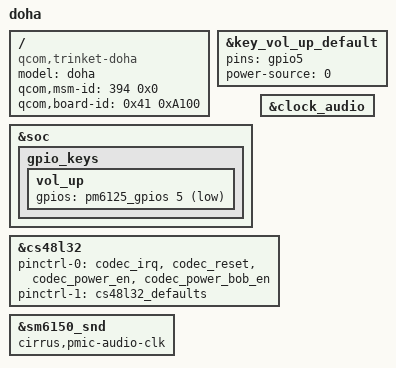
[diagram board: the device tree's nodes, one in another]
/* Copyright (c) 2018, The Linux Foundation. All rights reserved.
 *
 * This program is free software; you can redistribute it and/or modify
 * it under the terms of the GNU General Public License version 2 and
 * only version 2 as published by the Free Software Foundation.
 *
 * This program is distributed in the hope that it will be useful,
 * but WITHOUT ANY WARRANTY; without even the implied warranty of
 * MERCHANTABILITY or FITNESS FOR A PARTICULAR PURPOSE.  See the
 * GNU General Public License for more details.
 */

/dts-v1/;
/plugin/;

#include <dt-bindings/clock/qcom,gcc-trinket.h>
#include "trinket-doha-common-overlay.dtsi"

/ {
	model = "doha";
	compatible = "qcom,trinket-doha", "qcom,trinket-moto", "qcom,trinket";
	qcom,msm-id = <394 0x0>;
	qcom,board-id = <0x41 0xA100>;
};

&key_vol_up_default {
	pins = "gpio5";
	power-source = <0>;
};

&soc {
	gpio_keys {
		vol_up {
			gpios = <&pm6125_gpios 5 GPIO_ACTIVE_LOW>;
		};
	};
};

&clock_audio {
	status = "ok";
};

&cs48l32 {
	pinctrl-names = "probe", "active";
	pinctrl-0 = <&codec_irq &codec_reset &codec_power_en &codec_power_bob_en>;
	pinctrl-1 = <&cs48l32_defaults>;
};

&sm6150_snd {
	cirrus,pmic-audio-clk;
};
